# cslr_spi register map
Vendor: Texas Instruments
Peripheral module from a debugger description file (folder C5545).
Address unit: 16 bits
Registers are 16-bit, access not given, reset 0x0 unless marked. A register's access mark holds for its fields unless they carry their own. Offsets are as the file gives them; lines under a group give offsets from that group; [hi:lo] are bit positions; {n}, {i} and the like mark numbered series; 'fields as' and 'values as' point back to an identical list; <NAME> marks a mode.

## SPI — The SPI is a high-speed synchronous serial input/output port that allows a serial bit stream of programmed length (1 to 32 bits) to be shifted into and out of the device at a programmed bit-transfer rate. The SPI supports multi-chip operation of up to four SPI slave devices. The SPI can operate as a master device only.
0x00 SPICDR rw — The clock divider register (SPICDR) specifies the clock divider value for the SPI input clock.
  [15:0] CLKDV — Clock divider bits. The SPI input clock is divided down to generate the SPI interface clock (SPI_CLK). You can specify the divider value through the CLKDV bits. The frequency SPI_CLK is: SPI_CLK frequency = ( SPI input clock frequency ) / (CLKDV + 1) The duty cycle of SPI_CLK depends on the value of CLKDV + 1. When CLKDV + 1 is odd, the resulting duty cycle is approximately 33%. When CLKDV + 1 is even, the duty cycle is approximately 50%. NOTE: CLKDV must be set to a value greater than or equal to 2 such that the frequency of SPI_CLK is at least three times slower than the frequency of the SPI input clock.
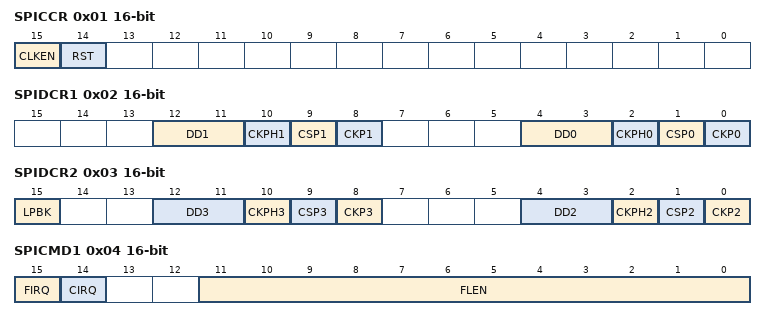
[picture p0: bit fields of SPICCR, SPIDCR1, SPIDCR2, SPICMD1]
0x01 SPICCR — The clock control register (SPICCR) is used to enable the clock output and to initiate a soft reset to the SPI module.
  [15] CLKEN rw — Clock enable bit. This bit is is used to enable and disable the SPI interface clock (SPI_CLK).
    0=DISABLED (SPI_CLK is disabled and held at the logic value specified by the clock polarity bit of SPIDC.); 1=ENABLED (SPI_CLK is enabled.)
  [14] RST wo — Soft reset bit. Writing a 1 to this bit will reset the SPI module. This bit is self-clearing and will deactivate the soft reset on the next SPI input clock cycle after this bit is set to 1.
    0=RELEASE (Soft reset is released.); 1=ASSERT (Soft reset is asserted.)
0x02 SPIDCR1 — The device configuration registers (SPIDCR1 and SPIDCR2) are used to specify the clock phase, clock polarity, and data delay for each SPI slave connected to the SPI chip select pins.
  [12:11] DD1 rw — Data delay for chip select 1 pin (SPI_CS1).
    0=DELAY0 (Data is output on the same cycle as the SPI_CS1 goes active.); 1=DELAY1 (Data is output one SPI_CLK cycle after the SPI_CS1 goes active.); 2=DELAY2 (Data is output two SPI_CLK cycles after the SPI_CS1 goes active.); 3=DELAY3 (Data is output three SPI_CLK cycles after the SPI_CS1 goes active.)
  [10] CKPH1 rw — Clock phase for chip select 1 pin (SPI_CS1). The clock phase bit, in conjunction with the clock polarity bit (CKP1), controls the clock-data relationship between master and slave.
    0=LOW (When CKP1 = 0, data shifted out on falling edge, input captured on rising edge. When CKP1 = 1, data shifted out on rising edge, input captured on falling edge.); 1=HIGH (When CKP1 = 0, data shifted out on rising edge, input captured on falling edge. When CKP1 = 1, data shifted out on falling edge, input captured on rising edge.)
  [9] CSP1 rw — Polarity for chip select 1 pin (SPI_CS1).
    0=LOW (Active low.); 1=HIGH (Active high.)
  [8] CKP1 rw — Clock polarity inactive state for the clock pin during accesses to chip select 1.
    0=LOW (When data is not being transferred, a steady state low value is produced at the SCK pin.); 1=HIGH (When data is not being transferred, a steady state high value is produced at the SCK pin.)
  [4:3] DD0 rw — Data delay for chip select 0 pin (SPI_CS0).
    0=DELAY0 (Data is output on the same cycle as the SPI_CS0 goes active.); 1=DELAY1 (Data is output one SPI_CLK cycle after the SPI_CS0 goes active.); 2=DELAY2 (Data is output two SPI_CLK cycles after the SPI_CS0 goes active.); 3=DELAY3 (Data is output three SPI_CLK cycles after the SPI_CS0 goes active.)
  [2] CKPH0 rw — Clock phase for chip select 0 pin (SPI_CS0). The clock phase bit, in conjunction with the clock polarity bit (CKP0), controls the clock-data relationship between master and slave.
    0=LOW (When CKP0 = 0, data shifted out on falling edge, input captured on rising edge. When CKP0 = 1, data shifted out on rising edge, input captured on falling edge.); 1=HIGH (When CKP0 = 0, data shifted out on rising edge, input captured on falling edge. When CKP0 = 1, data shifted out on falling edge, input captured on rising edge.)
  [1] CSP0 rw — Polarity for chip select 0 pin (SPI_CS0).
    0=LOW (Active low.); 1=HIGH (Active high.)
  [0] CKP0 rw — Clock polarity inactive state for the clock pin during accesses to chip select 0.
    values as CKP1
0x03 SPIDCR2 — The device configuration registers (SPIDCR1 and SPIDCR2) are used to specify the clock phase, clock polarity, and data delay for each SPI slave connected to the SPI chip select pins.
  [15] LPBK rw — Loopback mode enable bit.
    0=DISABLE (Loopback mode is disabled.); 1=ENABLE (Loopback mode is enabled.)
  [12:11] DD3 rw — Data delay for chip select 3 pin (SPI_CS3).
    0=DELAY0 (Data is output on the same cycle as the SPI_CS3 goes active.); 1=DELAY1 (Data is output one SPI_CLK cycle after the SPI_CS3 goes active.); 2=DELAY2 (Data is output two SPI_CLK cycles after the SPI_CS3 goes active.); 3=DELAY3 (Data is output three SPI_CLK cycles after the SPI_CS3 goes active.)
  [10] CKPH3 rw — Clock phase for chip select 3 pin (SPI_CS3). The clock phase bit, in conjunction with the clock polarity bit (CKP3), controls the clock-data relationship between master and slave.
    0=LOW (When CKP3 = 0, data shifted out on falling edge, input captured on rising edge. When CKP3 = 1, data shifted out on rising edge, input captured on falling edge.); 1=HIGH (When CKP3 = 0, data shifted out on rising edge, input captured on falling edge. When CKP3 = 1, data shifted out on falling edge, input captured on rising edge.)
  [9] CSP3 rw — Polarity for chip select 3 pin (SPI_CS3).
    0=LOW (Active low.); 1=HIGH (Active high.)
  [8] CKP3 rw — Clock polarity inactive state for the clock pin during accesses to chip select 3.
    values as SPIDCR1.CKP1
  [4:3] DD2 rw — Data delay for chip select 2 pin (SPI_CS2).
    0=DELAY0 (Data is output on the same cycle as the SPI_CS2 goes active.); 1=DELAY1 (Data is output one SPI_CLK cycle after the SPI_CS2 goes active.); 2=DELAY2 (Data is output two SPI_CLK cycles after the SPI_CS2 goes active.); 3=DELAY3 (Data is output three SPI_CLK cycles after the SPI_CS2 goes active.)
  [2] CKPH2 rw — Clock phase for chip select 2 pin (SPI_CS2). The clock phase bit, in conjunction with the clock polarity bit (CKP2), controls the clock-data relationship between master and slave.
    0=LOW (When CKP2 = 0, data shifted out on falling edge, input captured on rising edge. When CKP2 = 1, data shifted out on rising edge, input captured on falling edge.); 1=HIGH (When CKP2 = 0, data shifted out on rising edge, input captured on falling edge. When CKP2 = 1, data shifted out on falling edge, input captured on rising edge.)
  [1] CSP2 rw — Polarity for chip select 2 pin (SPI_CS2).
    0=LOW (Active low.); 1=HIGH (Active high.)
  [0] CKP2 rw — Clock polarity inactive state for the clock pin during accesses to chip select 2.
    values as SPIDCR1.CKP1
0x04 SPICMD1 — Used to enable character and frame complete interrupts and specify the number of characters in a frame.
  [15] FIRQ ro — Frame count interrupt enable.
    0=DISABLE (No interrupt generated at the end of the frame count.); 1=ENABLE (Interrupt generated at the end of the frame count.)
  [14] CIRQ rw — Character interrupt enable.
    0=DISABLE (No interrupt generated at the end of the character transfer.); 1=ENABLE (Interrupt generated at the end of the character transfer.)
  [11:0] FLEN rw — Frame length bits. These bits are used to specify the length of entire transfer. The total number of characters transferred equals FLEN + 1. For example, if FLEN = 63, a frame consists of a total of 64 characters.
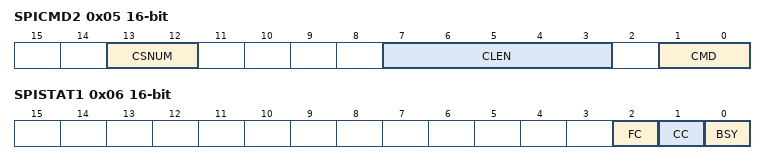
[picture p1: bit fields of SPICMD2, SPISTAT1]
0x05 SPICMD2 — The command to use (read or write), character length, and chip select pin used during SPI transfers are specified through SPICMD2. Writing to SPICMD2 will cause the SPI to execute the command specified by the transfer command bits (CMD).
  [13:12] CSNUM rw — Device select. Sets the active chip select for the transfer.
    {v}=CS{v} (Chip select {v} is active.) (v=0..3)
  [7:3] CLEN rw — Character length. Sets the transfer size of the individual transfer elements from 1 to 32 bits. The character length is set to CLEN + 1. For example, if CLEN = 7, the character length is set to 8 bits.
  [1:0] CMD rw — Transfer command bits. These bits specify the type of transaction being used.
    0=RSV1 (Reserved.); 1=READ; 2=RSV2 (Write.); 3=WRITE (Reserved.)
0x06 SPISTAT1 — The status registers (SPISTAT1 and SPISTAT2) contain indicators to allow you to monitor the progression of a frame transfer.
  [2] FC ro — Frame complete. This bit is set after all the requested characters have been transferred. This bit is reset when SPISTAT2 is read and when SPICMD2 is written to.
    0=NOTCOMPLETE (Transfer is not complete.); 1=COMPLETE (All characters have been transferred.)
  [1] CC ro — Character complete. This bit is set after each character transfer is completed. This bit is reset when SPISTAT2 is read and when SPICMD2 is written to.
    0=NOTCOMPLETE (Character transfer is not complete.); 1=COMPLETE (Character transfer is complete.)
  [0] BSY ro — Busy bit. This bit is set during an active character transfer. Between characters this bit will be cleared to signal that the data registers can be accessed.
    0=NOTBUSY (Idle, no character transfers in progress.); 1=BUSY (Active, a character transfer is in progress.)
0x07 SPISTAT2 — The status registers (SPISTAT1 and SPISTAT2) contain indicators to allow you to monitor the progression of a frame transfer.
  [12:0] CCNT ro — Character count. These bits reflect the total number of characters transferred minus one. For example, when CCNT = 63, a total of 64 characters have been transferred.
0x08 SPIDR1 rw — The data registers (SPIDAT1 and SPIDAT2) are treated as a 32-bit shift register. Data received by the SPI is shifted into the least-significant bit of SPIDAT1 and the contents of both registers are shifted to the left. Similarly, data transferred by the SPI is shifted out of the most-significant bit of SPIDAT2 and the contents of both registers are shifted to the left.
  [15:0] DATA — Low part of data during read and write operations.
0x09 SPIDR2 rw — The data registers (SPIDAT1 and SPIDAT2) are treated as a 32-bit shift register. Data received by the SPI is shifted into the least-significant bit of SPIDAT1 and the contents of both registers are shifted to the left. Similarly, data transferred by the SPI is shifted out of the most-significant bit of SPIDAT2 and the contents of both registers are shifted to the left.
  [15:0] DATA — High part of data during read and write operations.
